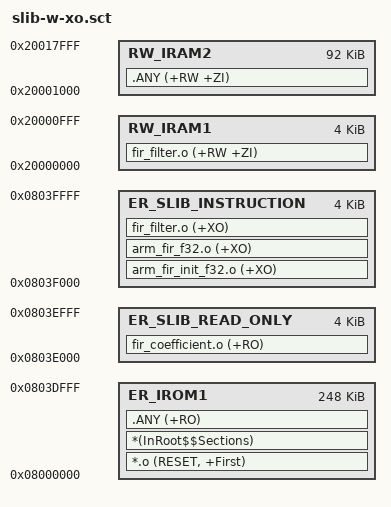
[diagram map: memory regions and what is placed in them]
; *************************************************************
; *** Scatter-Loading Description File generated by uVision ***
; *************************************************************

LR_IROM1 0x08000000 0x03E000  {    ; load region size_region
  ER_IROM1 0x08000000 0x03E000  {  ; load address = execution address
   *.o (RESET, +First)
   *(InRoot$$Sections)
   .ANY (+RO)
  }

  RW_IRAM1 0x20000000 0x00001000  {  ; RAM used for slib code
   fir_filter.o (+RW +ZI) 
  }

  RW_IRAM2 0x20001000 0x00017000  {  ; user RW data
   .ANY (+RW +ZI)
  }
}

LR_SLIB_READ_ONLY 0x0803E000 0x00001000  {    ; sLib read-only area
  ER_SLIB_READ_ONLY 0x0803E000 0x00001000  {  
   fir_coefficient.o (+RO)   
  }
}

LR_SLIB_INSTRUCTION 0x0803F000 0x00001000  {    ; slib instruction area
  ER_SLIB_INSTRUCTION 0x0803F000 0x00001000  {  ; load address = execution address
   arm_fir_init_f32.o (+XO)
   arm_fir_f32.o (+XO)
   fir_filter.o (+XO)
  }
}
